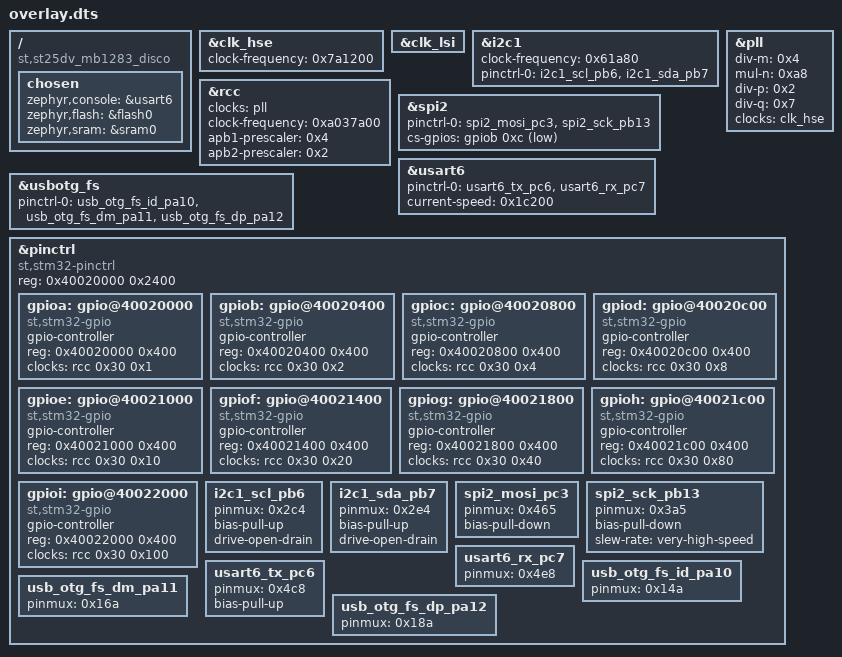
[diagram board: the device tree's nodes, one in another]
/ {
	compatible = "st,st25dv_mb1283_disco", "st,stm32f4", "st,stm32f405";
	chosen {
		zephyr,console = &usart6;
		zephyr,flash = &flash0;
		zephyr,sram = &sram0;
	};
};
&clk_hse{
	status = "okay";
	clock-frequency = < 0x7a1200 >;
};
&clk_lsi{
	status = "okay";
};
&i2c1{
	clock-frequency = < 0x61a80 >;
	status = "okay";
	pinctrl-0 = < &i2c1_scl_pb6 &i2c1_sda_pb7 >;
	pinctrl-names = "default";
};
&pll{
	status = "okay";
	div-m = < 0x4 >;
	mul-n = < 0xa8 >;
	div-p = < 0x2 >;
	div-q = < 0x7 >;
	clocks = < &clk_hse >;
};
&rcc{
	clocks = < &pll >;
	clock-frequency = < 0xa037a00 >;
	apb1-prescaler = < 0x4 >;
	apb2-prescaler = < 0x2 >;
};
&spi2{
	status = "okay";
	pinctrl-0 = < &spi2_mosi_pc3 &spi2_sck_pb13 >;
	cs-gpios = < &gpiob 0xc 0x11 >;
	pinctrl-names = "default";
};
&usart6{
	status = "okay";
	pinctrl-0 = < &usart6_tx_pc6 &usart6_rx_pc7 >;
	pinctrl-names = "default";
	current-speed = < 0x1c200 >;
};
&usbotg_fs{
	status = "okay";
	pinctrl-0 = < &usb_otg_fs_id_pa10 &usb_otg_fs_dm_pa11 &usb_otg_fs_dp_pa12 >;
	pinctrl-names = "default";
};
&pinctrl{
	compatible = "st,stm32-pinctrl";
	#address-cells = < 0x1 >;
	#size-cells = < 0x1 >;
	reg = < 0x40020000 0x2400 >;
	gpioa: gpio@40020000 {
		compatible = "st,stm32-gpio";
		gpio-controller;
		#gpio-cells = < 0x2 >;
		reg = < 0x40020000 0x400 >;
		clocks = < &rcc 0x30 0x1 >;
	};
	gpiob: gpio@40020400 {
		compatible = "st,stm32-gpio";
		gpio-controller;
		#gpio-cells = < 0x2 >;
		reg = < 0x40020400 0x400 >;
		clocks = < &rcc 0x30 0x2 >;
	};
	gpioc: gpio@40020800 {
		compatible = "st,stm32-gpio";
		gpio-controller;
		#gpio-cells = < 0x2 >;
		reg = < 0x40020800 0x400 >;
		clocks = < &rcc 0x30 0x4 >;
	};
	gpiod: gpio@40020c00 {
		compatible = "st,stm32-gpio";
		gpio-controller;
		#gpio-cells = < 0x2 >;
		reg = < 0x40020c00 0x400 >;
		clocks = < &rcc 0x30 0x8 >;
	};
	gpioe: gpio@40021000 {
		compatible = "st,stm32-gpio";
		gpio-controller;
		#gpio-cells = < 0x2 >;
		reg = < 0x40021000 0x400 >;
		clocks = < &rcc 0x30 0x10 >;
	};
	gpiof: gpio@40021400 {
		compatible = "st,stm32-gpio";
		gpio-controller;
		#gpio-cells = < 0x2 >;
		reg = < 0x40021400 0x400 >;
		clocks = < &rcc 0x30 0x20 >;
	};
	gpiog: gpio@40021800 {
		compatible = "st,stm32-gpio";
		gpio-controller;
		#gpio-cells = < 0x2 >;
		reg = < 0x40021800 0x400 >;
		clocks = < &rcc 0x30 0x40 >;
	};
	gpioh: gpio@40021c00 {
		compatible = "st,stm32-gpio";
		gpio-controller;
		#gpio-cells = < 0x2 >;
		reg = < 0x40021c00 0x400 >;
		clocks = < &rcc 0x30 0x80 >;
	};
	gpioi: gpio@40022000 {
		compatible = "st,stm32-gpio";
		gpio-controller;
		#gpio-cells = < 0x2 >;
		reg = < 0x40022000 0x400 >;
		clocks = < &rcc 0x30 0x100 >;
	};
	i2c1_scl_pb6: i2c1_scl_pb6 {
		pinmux = < 0x2c4 >;
		bias-pull-up;
		drive-open-drain;
	};
	i2c1_sda_pb7: i2c1_sda_pb7 {
		pinmux = < 0x2e4 >;
		bias-pull-up;
		drive-open-drain;
	};
	spi2_mosi_pc3: spi2_mosi_pc3 {
		pinmux = < 0x465 >;
		bias-pull-down;
	};
	spi2_sck_pb13: spi2_sck_pb13 {
		pinmux = < 0x3a5 >;
		bias-pull-down;
		slew-rate = "very-high-speed";
	};
	usart6_rx_pc7: usart6_rx_pc7 {
		pinmux = < 0x4e8 >;
	};
	usart6_tx_pc6: usart6_tx_pc6 {
		pinmux = < 0x4c8 >;
		bias-pull-up;
	};
	usb_otg_fs_id_pa10: usb_otg_fs_id_pa10 {
		pinmux = < 0x14a >;
	};
	usb_otg_fs_dm_pa11: usb_otg_fs_dm_pa11 {
		pinmux = < 0x16a >;
	};
	usb_otg_fs_dp_pa12: usb_otg_fs_dp_pa12 {
		pinmux = < 0x18a >;
	};
};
